AUTOSAR XML (schema 4.0)
standard types defined: float32, float64, sint16, sint32, sint8, uint16, uint32, uint8, void, boolean
package /ImplDataTypes
  impl type MultiStateBtn: implementation-data-type=uint8, type-emitter=RTE
package /MappingSets
  data type mapping set MappingSet
package /PortInterfaces/SenderReceiver
  sender receiver interface Srlf_SeatCtrlBtns
    data HeightBtnState: type=MultiStateBtn
    data InclineBtnState: type=MultiStateBtn
    data SlideBtnState: type=MultiStateBtn
  sender receiver interface Srlf_SeatCtrlData
    data Height: type=uint8
    data Incline: type=uint8
    data Slide: type=uint8
package /SoftwareComponents
  application sw component type ECU
    provide port ppSeatCtrlData: provided-interface=Srlf_SeatCtrlData
    behavior Ibhv_ECU: data-type-mapping=MappingSet, handle-termination-and-restart=NO-SUPPORT
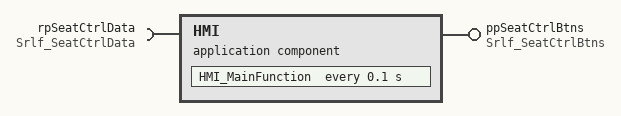
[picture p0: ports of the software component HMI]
  application sw component type HMI
    provide port ppSeatCtrlBtns: provided-interface=Srlf_SeatCtrlBtns
    require port rpSeatCtrlData: required-interface=Srlf_SeatCtrlData
    behavior Ibhv_HMI: data-type-mapping=MappingSet, handle-termination-and-restart=NO-SUPPORT
      timing event TE_HMI_MainFunction_100ms: start-on-event=HMI_MainFunction, period=0.1
      runnable HMI_MainFunction
        data-receive-point-by-arguments:
          access DRP_rpSeatCtrlData_Height: accessed-variable=rpSeatCtrlData.Height
          access DRP_rpSeatCtrlData_Incline: accessed-variable=rpSeatCtrlData.Incline
          access DRP_rpSeatCtrlData_Slide: accessed-variable=rpSeatCtrlData.Slide
        data-send-points:
          access DSP_ppSeatCtrlBtns_HeightBtnState: accessed-variable=ppSeatCtrlBtns.HeightBtnState
          access DSP_ppSeatCtrlBtns_InclineBtnState: accessed-variable=ppSeatCtrlBtns.InclineBtnState
          access DSP_ppSeatCtrlBtns_SlideBtnState: accessed-variable=ppSeatCtrlBtns.SlideBtnState
  swc implementation Impl_ECU: programming-language=C, sw-version=1.0.0, vendor-id=255, behavior=Ibhv_ECU
    code-descriptors:
      code Code: artifact-descriptors=autosar-engineering-object={short-label=SWC.c, category=SWSRC}
    resource consumption ResourceConsumption
  swc implementation Impl_HMI: programming-language=C, sw-version=1.0.0, vendor-id=255, behavior=Ibhv_HMI
    code-descriptors:
      code Code: artifact-descriptors=autosar-engineering-object={short-label=SWC.c, category=SWSRC}
    resource consumption ResourceConsumption
  swc implementation Impl_Seat_Manager: programming-language=C, sw-version=1.0.0, vendor-id=255, behavior=Ibhv_Seat_Manager
    code-descriptors:
      code Code: artifact-descriptors=autosar-engineering-object={short-label=SWC.c, category=SWSRC}
    resource consumption ResourceConsumption
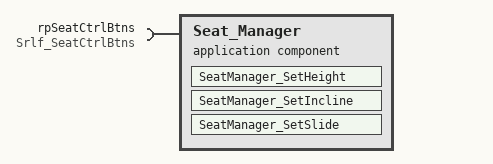
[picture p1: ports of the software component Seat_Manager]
  application sw component type Seat_Manager
    require port rpSeatCtrlBtns: required-interface=Srlf_SeatCtrlBtns
    behavior Ibhv_Seat_Manager: data-type-mapping=MappingSet, handle-termination-and-restart=NO-SUPPORT
      data received event DRE_rpSeatCtrlBtns_HeightBtnState: start-on-event=SeatManager_SetHeight, data=rpSeatCtrlBtns.HeightBtnState
      data received event DRE_rpSeatCtrlBtns_SlideBtnState: start-on-event=SeatManager_SetSlide, data=rpSeatCtrlBtns.SlideBtnState
      data received event DRE_rpSeatCtrlBtns_SlideBtnState: start-on-event=SeatManager_SetIncline, data=rpSeatCtrlBtns.SlideBtnState
      runnable SeatManager_SetHeight
        data-receive-point-by-arguments:
          access DRP_rpSeatCtrlBtns_HeightBtnState: accessed-variable=rpSeatCtrlBtns.HeightBtnState
      runnable SeatManager_SetIncline
        data-receive-point-by-arguments:
          access DRP_rpSeatCtrlBtns_InclineBtnState: accessed-variable=rpSeatCtrlBtns.InclineBtnState
      runnable SeatManager_SetSlide
        data-receive-point-by-arguments:
          access DRP_rpSeatCtrlBtns_SlideBtnState: accessed-variable=rpSeatCtrlBtns.SlideBtnState
package /Compositions
  composition sw component type Task2Composition
    component ECU: type=ECU
    component HMI: type=HMI
    component Seat_Manager: type=Seat_Manager
    connect ECU.ppSeatCtrlData -> HMI.rpSeatCtrlData
    connect HMI.ppSeatCtrlBtns -> Seat_Manager.rpSeatCtrlBtns
